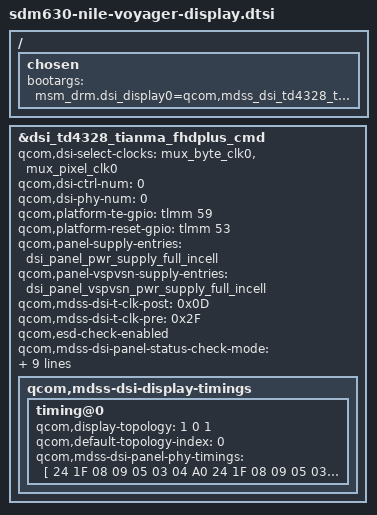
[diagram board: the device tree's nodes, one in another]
// SPDX-License-Identifier: GPL-2.0-only
/*
 * Copyright (c) 2017-2021, The Linux Foundation. All rights reserved.
 */

#include "dsi-panel-td4328-tianma-fhdplus-cmd.dtsi"

/ {
	chosen {
		bootargs = "msm_drm.dsi_display0=qcom,mdss_dsi_td4328_tianma_fhdplus_cmd:config0";
	};
};

&dsi_td4328_tianma_fhdplus_cmd {
	qcom,dsi-select-clocks = "mux_byte_clk0", "mux_pixel_clk0";
	qcom,dsi-ctrl-num = <0>;
	qcom,dsi-phy-num = <0>;

	qcom,platform-te-gpio = <&tlmm 59 0>;
	qcom,platform-reset-gpio = <&tlmm 53 0>;

	qcom,panel-supply-entries = <&dsi_panel_pwr_supply_full_incell>;
	qcom,panel-vspvsn-supply-entries = <&dsi_panel_vspvsn_pwr_supply_full_incell>;

	qcom,mdss-dsi-t-clk-post = <0x0D>;
	qcom,mdss-dsi-t-clk-pre = <0x2F>;
	qcom,esd-check-enabled;
	qcom,mdss-dsi-panel-status-check-mode = "reg_read";
	qcom,mdss-dsi-panel-status-command = [06 01 00 01 00 00 01 0A];
	qcom,mdss-dsi-panel-status-command-state = "dsi_hs_mode";
	qcom,mdss-dsi-panel-status-value = <0x1C>;
	qcom,mdss-dsi-panel-status-read-length = <1>;
	qcom,mdss-dsi-te-using-wd;

	somc,dsi-panel-type = "lcd";

	qcom,mdss-dsi-display-timings {
		timing@0 {
			qcom,display-topology = <1 0 1>;
			qcom,default-topology-index = <0>;
			qcom,mdss-dsi-panel-phy-timings = [
				24 1F 08 09 05 03 04 A0
				24 1F 08 09 05 03 04 A0
				24 1F 08 09 05 03 04 A0
				24 1F 08 09 05 03 04 A0
				24 1C 08 09 05 03 04 A0
			];
		};
	};
};
